# STM32C031xx register map
File version: 1.0
Registers are 32-bit, read-write, reset 0x0 unless marked. A register's access mark holds for its fields unless they carry their own. Offsets are from the block's base; [hi:lo] are bit positions; {n}, {i} and the like mark numbered series; 'fields as' and 'values as' point back to an identical list.

## DBG — Debug MCU
Base 0x40015800
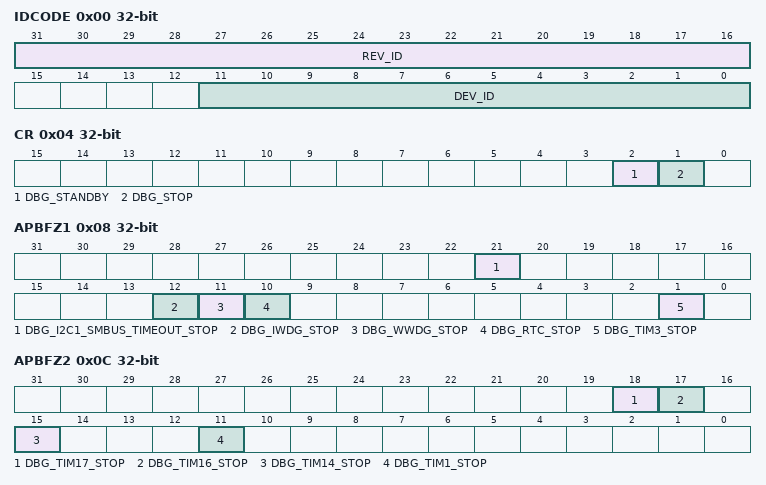
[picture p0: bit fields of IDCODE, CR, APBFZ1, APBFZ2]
0x00 IDCODE — MCU device ID code
  [31:16] REV_ID, [11:0] DEV_ID
0x04 CR — Debug configuration register
  [2] DBG_STANDBY, [1] DBG_STOP
0x08 APBFZ1 — Debug APB freeze register 1
  [21] DBG_I2C1_SMBUS_TIMEOUT_STOP, [12] DBG_IWDG_STOP, [11] DBG_WWDG_STOP, [10] DBG_RTC_STOP, [1] DBG_TIM3_STOP
0x0C APBFZ2 — Debug APB freeze register 2
  [18] DBG_TIM17_STOP, [17] DBG_TIM16_STOP, [15] DBG_TIM14_STOP, [11] DBG_TIM1_STOP

## DMA1
Base 0x40020000
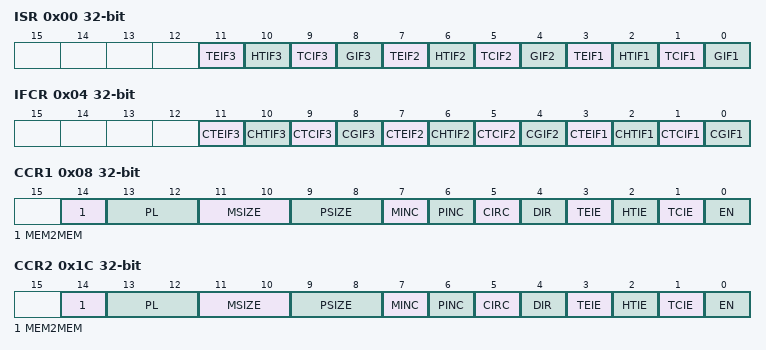
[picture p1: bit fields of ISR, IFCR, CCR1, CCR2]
0x00 ISR — DMA interrupt status register
  [11] TEIF3 — Channel 3 Transfer Error flag
  [10] HTIF3 — Channel 3 Half Transfer flag
  [9] TCIF3 — Channel 3 Transfer Complete flag
  [8] GIF3 — Channel 3 Global interrupt flag
  [7] TEIF2 — Channel 2 Transfer Error flag
  [6] HTIF2 — Channel 2 Half Transfer flag
  [5] TCIF2 — Channel 2 Transfer Complete flag
  [4] GIF2 — Channel 2 Global interrupt flag
  [3] TEIF1 — Channel 1 Transfer Error flag
  [2] HTIF1 — Channel 1 Half Transfer flag
  [1] TCIF1 — Channel 1 Transfer Complete flag
  [0] GIF1 — Channel 1 Global interrupt flag
0x04 IFCR — DMA interrupt flag clear register
  [11] CTEIF3 — Channel 3 Transfer Error clear
  [10] CHTIF3 — Channel 3 Half Transfer clear
  [9] CTCIF3 — Channel 3 Transfer Complete clear
  [8] CGIF3 — Channel 3 Global interrupt clear
  [7] CTEIF2 — Channel 2 Transfer Error clear
  [6] CHTIF2 — Channel 2 Half Transfer clear
  [5] CTCIF2 — Channel 2 Transfer Complete clear
  [4] CGIF2 — Channel 2 Global interrupt clear
  [3] CTEIF1 — Channel 1 Transfer Error clear
  [2] CHTIF1 — Channel 1 Half Transfer clear
  [1] CTCIF1 — Channel 1 Transfer Complete clear
  [0] CGIF1 — Channel 1 Global interrupt clearr
0x08 CCR1 — DMA channel x configuration register
  [14] MEM2MEM — Memory to memory mode
  [13:12] PL — PL[1:0] bits(Channel Priority level)
  [11:10] MSIZE — MSIZE[1:0] bits (Memory size)
  [9:8] PSIZE — PSIZE[1:0] bits (Peripheral size)
  [7] MINC — Memory increment mode
  [6] PINC — Peripheral increment mode
  [5] CIRC — Circular mode
  [4] DIR — Data transfer direction
  [3] TEIE — Transfer error interrupt enable
  [2] HTIE — Half Transfer interrupt enable
  [1] TCIE — Transfer complete interrupt enable
  [0] EN — Channel enable
0x0C CNDTR1 — DMA channel x number of data register
  [15:0] NDT — Number of data to Transfer
0x10 CPAR1 — DMA channel x peripheral address register
  [31:0] PA — Peripheral Address
{0x0+0x14*i} CMAR{i} (i=1..3) — DMA channel x memory address register
  [31:0] MA — Memory Address
0x1C CCR2 — DMA channel x configuration register
  fields as CCR1
0x20 CNDTR2 — DMA channel x number of data register
  [15:0] NDT — Number of data to Transfer
0x24 CPAR2 — DMA channel x peripheral address register
  [31:0] PA — Peripheral Address
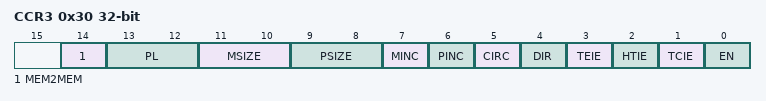
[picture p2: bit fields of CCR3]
0x30 CCR3 — DMA channel x configuration register
  fields as CCR1
0x34 CNDTR3 — DMA channel x number of data register
  [15:0] NDT — Number of data to Transfer
0x38 CPAR3 — DMA channel x peripheral address register
  [31:0] PA — Peripheral Address

## DMAMUX1 — DMA Multiplexer
Base 0x40020800
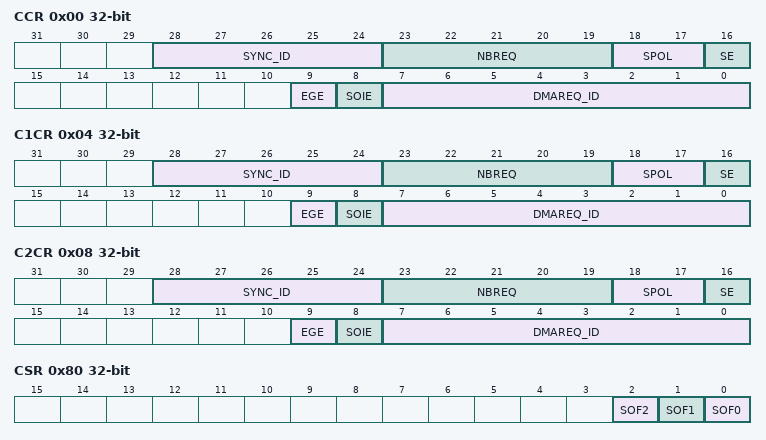
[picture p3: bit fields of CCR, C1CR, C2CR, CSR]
0x00 CCR — DMA Multiplexer Channel x Control Register
  [28:24] SYNC_ID — Synchronization ID
  [23:19] NBREQ — Number of request
  [18:17] SPOL — Synchronization polarity
  [16] SE — Synchronization enable
  [9] EGE — Event generation interrupt enable
  [8] SOIE — Synchro overrun interrupt enable
  [7:0] DMAREQ_ID — DMA Request ID
0x04 C1CR — DMA Multiplexer Channel x Control Register
  fields as CCR
0x08 C2CR — DMA Multiplexer Channel x Control Register
  fields as CCR
0x80 CSR — DMA Channel Status Register
  [2] SOF2 — Synchronization Overrun Flag 2
  [1] SOF1 — Synchronization Overrun Flag 1
  [0] SOF0 — Synchronization Overrun Flag 0
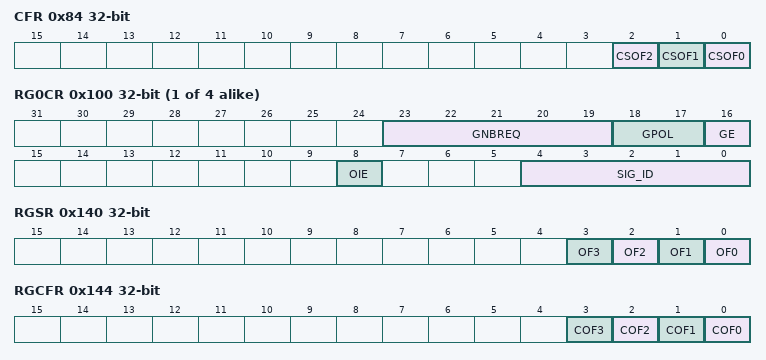
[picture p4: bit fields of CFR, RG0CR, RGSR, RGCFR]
0x84 CFR — DMA Channel Clear Flag Register
  [2] CSOF2 — Clear Overrun Flag 2
  [1] CSOF1 — Clear Overrun Flag 1
  [0] CSOF0 — Clear Overrun Flag 0
{0x100+4i} RG{i}CR (i=0..3) — DMA Request Generator x Control Register
  [23:19] GNBREQ — Number of request
  [18:17] GPOL — Generation polarity
  [16] GE — Generation enable
  [8] OIE — Overrun interrupt enable
  [4:0] SIG_ID — Signal ID
0x140 RGSR — DMA Request Generator Status Register
  [n] OF{n} (n=0..3) — Overrun flag {n}
0x144 RGCFR — DMA Request Generator Clear Flag Register
  [n] COF{n} (n=0..3) — Clear Overrun flag {n}
